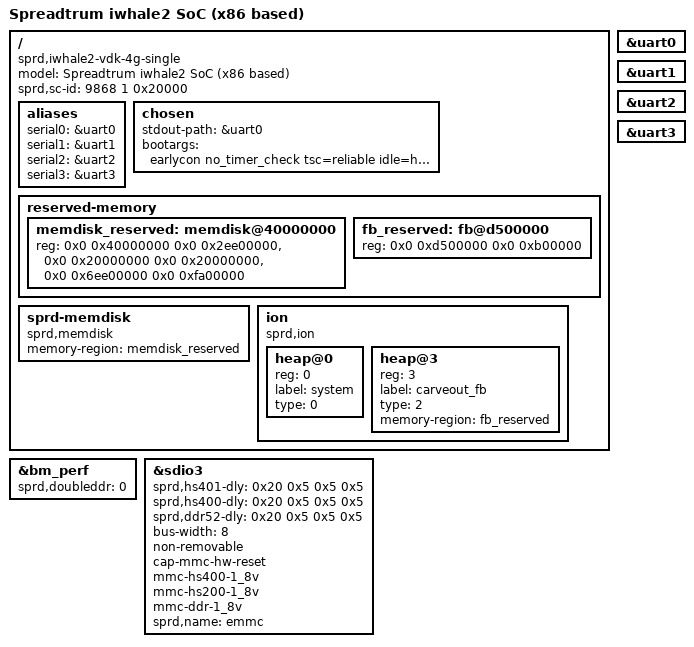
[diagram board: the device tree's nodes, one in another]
/*
 * Spreadtrum iwhale2 vdk board DTS file
 *
 * Copyright (C) 2015, Spreadtrum Communications Inc.
 *
 * This file is licensed under a dual GPLv2 or X11 license.
 */

/dts-v1/;

#include "irq-hw-sc9861.h"
#include "bia.dtsi"
#include "sc9861.dtsi"

/ {
	model = "Spreadtrum iwhale2 SoC (x86 based)";

	compatible = "sprd,iwhale2-vdk-4g-single","sprd,iwhale2-vdk";

	sprd,sc-id = <9868 1 0x20000>;

	aliases {
		serial0 = &uart0;
		serial1 = &uart1;
		serial2 = &uart2;
		serial3 = &uart3;
	};

	chosen {
		stdout-path = &uart0;
		bootargs = "earlycon no_timer_check tsc=reliable idle=halt console=ttyS0,921600n8 androidboot.hardware=sp9861 pit_freq=1147290 hpet_freq=25000000";
	};

	reserved-memory {
		#address-cells = <2>;
		#size-cells = <2>;
		ranges;

		memdisk_reserved: memdisk@40000000{
			reg = <0x0 0x40000000 0x0 0x2ee00000>, /* system 750M*/
				<0x0 0x20000000 0x0 0x20000000>, /* userdata 512M*/
				<0x0 0x6ee00000 0x0 0xfa00000>; /* cache 250M*/
		};

		fb_reserved: fb@d500000{
			reg = <0x0 0xd500000 0x0 0xb00000>; /* fb */
		};
	};

	sprd-memdisk {
		compatible = "sprd,memdisk";
		memory-region = <&memdisk_reserved>;
	};

	ion {
		compatible = "sprd,ion";
		#address-cells = <1>;
		#size-cells = <0>;

		heap@0 {
			reg = <0>;
			label = "system";
			type = <0>;
		};

		heap@3 {
			reg = <3>;
			label = "carveout_fb";
			type = <2>;
			memory-region = <&fb_reserved>;
		};
	};


};

&uart0 {
	status = "okay";
};

&uart1 {
	status = "okay";
};

&uart2 {
	status = "okay";
};

&uart3 {
	status = "okay";
};

&bm_perf {
	sprd,doubleddr = <0>;
};

&sdio3 {
	sprd,hs401-dly = <0x20 0x5 0x5 0x5>;
	sprd,hs400-dly = <0x20 0x5 0x5 0x5>;
	sprd,ddr52-dly = <0x20 0x5 0x5 0x5>;
	bus-width = <8>;
	non-removable;
	cap-mmc-hw-reset;
	mmc-hs400-1_8v;
	mmc-hs200-1_8v;
	mmc-ddr-1_8v;
	sprd,name = "emmc";
	status = "okay";
};
